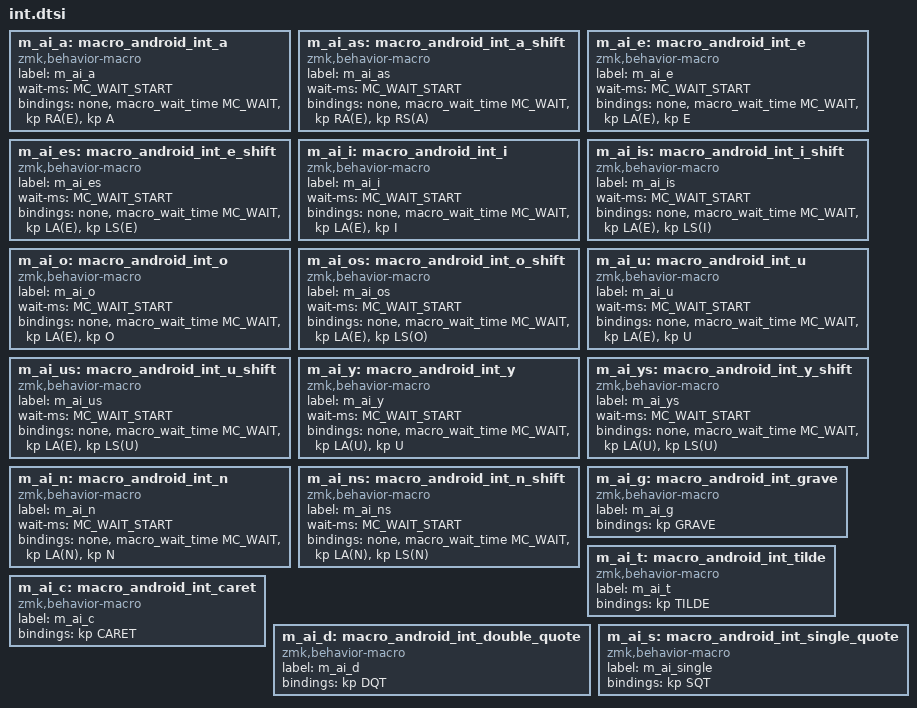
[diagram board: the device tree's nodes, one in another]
// action:     á
m_ai_a: macro_android_int_a {
    compatible = "zmk,behavior-macro";
    label = "m_ai_a";
    #binding-cells = <0>;
    wait-ms = <MC_WAIT_START>;
    bindings
        = <&none>
        , <&macro_wait_time MC_WAIT>
        , <&kp RA(E)>
        , <&kp A>;
};

// action:     Á
m_ai_as: macro_android_int_a_shift {
    compatible = "zmk,behavior-macro";
    label = "m_ai_as";
    #binding-cells = <0>;
    wait-ms = <MC_WAIT_START>;
    bindings
        = <&none>
        , <&macro_wait_time MC_WAIT>
        , <&kp RA(E)>
        , <&kp RS(A)>;
};

// action:     é
m_ai_e: macro_android_int_e {
    compatible = "zmk,behavior-macro";
    label = "m_ai_e";
    #binding-cells = <0>;
    wait-ms = <MC_WAIT_START>;
    bindings
        = <&none>
        , <&macro_wait_time MC_WAIT>
        , <&kp LA(E)>
        , <&kp E>;
};

// action:     É
m_ai_es: macro_android_int_e_shift {
    compatible = "zmk,behavior-macro";
    label = "m_ai_es";
    #binding-cells = <0>;
    wait-ms = <MC_WAIT_START>;
    bindings
        = <&none>
        , <&macro_wait_time MC_WAIT>
        , <&kp LA(E)>
        , <&kp LS(E)>;
};

// action:     í
m_ai_i: macro_android_int_i {
    compatible = "zmk,behavior-macro";
    label = "m_ai_i";
    #binding-cells = <0>;
    wait-ms = <MC_WAIT_START>;
    bindings
        = <&none>
        , <&macro_wait_time MC_WAIT>
        , <&kp LA(E)>
        , <&kp I>;
};

// action:     Í
m_ai_is: macro_android_int_i_shift {
    compatible = "zmk,behavior-macro";
    label = "m_ai_is";
    #binding-cells = <0>;
    wait-ms = <MC_WAIT_START>;
    bindings
        = <&none>
        , <&macro_wait_time MC_WAIT>
        , <&kp LA(E)>
        , <&kp LS(I)>;
};

// action:     ó
m_ai_o: macro_android_int_o {
    compatible = "zmk,behavior-macro";
    label = "m_ai_o";
    #binding-cells = <0>;
    wait-ms = <MC_WAIT_START>;
    bindings
        = <&none>
        , <&macro_wait_time MC_WAIT>
        , <&kp LA(E)>
        , <&kp O>;
};

// action:     Ó
m_ai_os: macro_android_int_o_shift {
    compatible = "zmk,behavior-macro";
    label = "m_ai_os";
    #binding-cells = <0>;
    wait-ms = <MC_WAIT_START>;
    bindings
        = <&none>
        , <&macro_wait_time MC_WAIT>
        , <&kp LA(E)>
        , <&kp LS(O)>;
};

// action:     ú
m_ai_u: macro_android_int_u {
    compatible = "zmk,behavior-macro";
    label = "m_ai_u";
    #binding-cells = <0>;
    wait-ms = <MC_WAIT_START>;
    bindings
        = <&none>
        , <&macro_wait_time MC_WAIT>
        , <&kp LA(E)>
        , <&kp U>;
};

// action:     Ú
m_ai_us: macro_android_int_u_shift {
    compatible = "zmk,behavior-macro";
    label = "m_ai_us";
    #binding-cells = <0>;
    wait-ms = <MC_WAIT_START>;
    bindings
        = <&none>
        , <&macro_wait_time MC_WAIT>
        , <&kp LA(E)>
        , <&kp LS(U)>;
};

// action:     ü
m_ai_y: macro_android_int_y {
    compatible = "zmk,behavior-macro";
    label = "m_ai_y";
    #binding-cells = <0>;
    wait-ms = <MC_WAIT_START>;
    bindings
        = <&none>
        , <&macro_wait_time MC_WAIT>
        , <&kp LA(U)>
        , <&kp U>;
};

// action:     Ü
m_ai_ys: macro_android_int_y_shift {
    compatible = "zmk,behavior-macro";
    label = "m_ai_ys";
    #binding-cells = <0>;
    wait-ms = <MC_WAIT_START>;
    bindings
        = <&none>
        , <&macro_wait_time MC_WAIT>
        , <&kp LA(U)>
        , <&kp LS(U)>;
};

// action:     ñ
m_ai_n: macro_android_int_n {
    compatible = "zmk,behavior-macro";
    label = "m_ai_n";
    #binding-cells = <0>;
    wait-ms = <MC_WAIT_START>;
    bindings
        = <&none>
        , <&macro_wait_time MC_WAIT>
        , <&kp LA(N)>
        , <&kp N>;
};

// action:     Ñ
m_ai_ns: macro_android_int_n_shift {
    compatible = "zmk,behavior-macro";
    label = "m_ai_ns";
    #binding-cells = <0>;
    wait-ms = <MC_WAIT_START>;
    bindings
        = <&none>
        , <&macro_wait_time MC_WAIT>
        , <&kp LA(N)>
        , <&kp LS(N)>;
};

// action:     `
m_ai_g: macro_android_int_grave {
    compatible = "zmk,behavior-macro";
    label = "m_ai_g";
    #binding-cells = <0>;
    bindings =
        <&kp GRAVE>;
};

// action:     ~
m_ai_t: macro_android_int_tilde {
    compatible = "zmk,behavior-macro";
    label = "m_ai_t";
    #binding-cells = <0>;
    bindings =
        <&kp TILDE>;
};

// action:     ^
m_ai_c: macro_android_int_caret {
    compatible = "zmk,behavior-macro";
    label = "m_ai_c";
    #binding-cells = <0>;
    bindings =
        <&kp CARET>;
};

// action:     "
m_ai_d: macro_android_int_double_quote {
    compatible = "zmk,behavior-macro";
    label = "m_ai_d";
    #binding-cells = <0>;
    bindings =
        <&kp DQT>;
};

// action:     '
m_ai_s: macro_android_int_single_quote {
    compatible = "zmk,behavior-macro";
    label = "m_ai_single";
    #binding-cells = <0>;
    bindings =
        <&kp SQT>;
};
